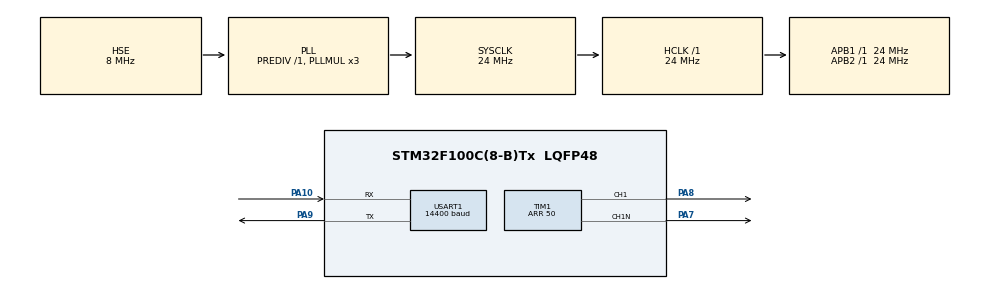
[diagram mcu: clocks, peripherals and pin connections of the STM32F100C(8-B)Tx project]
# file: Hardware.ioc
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Dma.Request0=USART1_TX
Dma.USART1_TX.0.Direction=DMA_MEMORY_TO_PERIPH
Dma.USART1_TX.0.Instance=DMA1_Channel4
Dma.USART1_TX.0.MemDataAlignment=DMA_MDATAALIGN_BYTE
Dma.USART1_TX.0.MemInc=DMA_MINC_ENABLE
Dma.USART1_TX.0.Mode=DMA_NORMAL
Dma.USART1_TX.0.PeriphDataAlignment=DMA_PDATAALIGN_BYTE
Dma.USART1_TX.0.PeriphInc=DMA_PINC_DISABLE
Dma.USART1_TX.0.Priority=DMA_PRIORITY_LOW
Mcu.Family=STM32F1
Mcu.Name=STM32F100C(8-B)Tx
Mcu.Package=LQFP48
NVIC.DMA1_Channel4_IRQn=true\:5\:0\:false\:false\:true\:true\:false
NVIC.PriorityGroup=NVIC_PRIORITYGROUP_4
NVIC.TIM3_IRQn=true\:5\:0\:false\:false\:true\:true\:true
NVIC.TIM7_IRQn=true\:0\:0\:false\:false\:true\:false\:false
NVIC.TimeBase=TIM7_IRQn
NVIC.TimeBaseIP=TIM7
NVIC.USART1_IRQn=true\:5\:0\:false\:false\:true\:true\:true
PA10.Mode=Asynchronous
PA10.Signal=USART1_RX
PA13.Mode=Serial_Wire
PA13.Signal=SYS_JTMS-SWDIO
PA14.Mode=Serial_Wire
PA14.Signal=SYS_JTCK-SWCLK
PA7.GPIO_Speed=GPIO_SPEED_FREQ_HIGH
PA7.Mode=PWM Generation1 CH1 CH1N
PA7.Signal=TIM1_CH1N
PA8.GPIO_Speed=GPIO_SPEED_FREQ_HIGH
PA8.Signal=S_TIM1_CH1
PA9.Mode=Asynchronous
PA9.Signal=USART1_TX
PD0-OSC_IN.Mode=HSE-External-Oscillator
PD0-OSC_IN.Signal=RCC_OSC_IN
PD1-OSC_OUT.Mode=HSE-External-Oscillator
PD1-OSC_OUT.Signal=RCC_OSC_OUT
ProjectManager.HeapSize=0x200
ProjectManager.StackSize=0x400
ProjectManager.TargetToolchain=SW4STM32
RCC.AHBFreq_Value=24000000
RCC.APB1Freq_Value=24000000
RCC.APB1TimFreq_Value=24000000
RCC.APB2Freq_Value=24000000
RCC.APB2TimFreq_Value=24000000
RCC.HCLKFreq_Value=24000000
RCC.PLLMUL=RCC_PLL_MUL3
RCC.PLLSource=RCC_PLLSOURCE_HSE
RCC.SYSCLKFreq_VALUE=24000000
RCC.SYSCLKSource=RCC_SYSCLKSOURCE_PLLCLK
SH.S_TIM1_CH1.0=TIM1_CH1,PWM Generation1 CH1 CH1N
TIM1.AutoReloadPreload=TIM_AUTORELOAD_PRELOAD_ENABLE
TIM1.Channel-PWM\ Generation1\ CH1\ CH1N=TIM_CHANNEL_1
TIM1.DeadTime=1
TIM1.Period=50
TIM1.Pulse-PWM\ Generation1\ CH1\ CH1N=25
TIM3.AutoReloadPreload=TIM_AUTORELOAD_PRELOAD_ENABLE
TIM3.Period=200
USART1.BaudRate=14400
USART1.VirtualMode=VM_ASYNC
VP_SYS_VS_tim7.Mode=TIM7
VP_TIM1_VS_ClockSourceINT.Mode=Internal
VP_TIM3_VS_ClockSourceINT.Mode=Internal
board=custom

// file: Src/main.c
/* USER CODE BEGIN Header */
/**
  ******************************************************************************
  * @file           : main.c
  * @brief          : Main program body
  ******************************************************************************
  * This notice applies to any and all portions of this file
  * that are not between comment pairs USER CODE BEGIN and
  * USER CODE END. Other portions of this file, whether
  * inserted by the user or by software development tools
  * are owned by their respective copyright owners.
  *
  * Copyright (c) 2019 STMicroelectronics International N.V.
  * All rights reserved.
  *
  * Redistribution and use in source and binary forms, with or without
  * modification, are permitted, provided that the following conditions are met:
  *
  * 1. Redistribution of source code must retain the above copyright notice,
  *    this list of conditions and the following disclaimer.
  * 2. Redistributions in binary form must reproduce the above copyright notice,
  *    this list of conditions and the following disclaimer in the documentation
  *    and/or other materials provided with the distribution.
  * 3. Neither the name of STMicroelectronics nor the names of other
  *    contributors to this software may be used to endorse or promote products
  *    derived from this software without specific written permission.
  * 4. This software, including modifications and/or derivative works of this
  *    software, must execute solely and exclusively on microcontroller or
  *    microprocessor devices manufactured by or for STMicroelectronics.
  * 5. Redistribution and use of this software other than as permitted under
  *    this license is void and will automatically terminate your rights under
  *    this license.
  *
  * THIS SOFTWARE IS PROVIDED BY STMICROELECTRONICS AND CONTRIBUTORS "AS IS"
  * AND ANY EXPRESS, IMPLIED OR STATUTORY WARRANTIES, INCLUDING, BUT NOT
  * LIMITED TO, THE IMPLIED WARRANTIES OF MERCHANTABILITY, FITNESS FOR A
  * PARTICULAR PURPOSE AND NON-INFRINGEMENT OF THIRD PARTY INTELLECTUAL PROPERTY
  * RIGHTS ARE DISCLAIMED TO THE FULLEST EXTENT PERMITTED BY LAW. IN NO EVENT
  * SHALL STMICROELECTRONICS OR CONTRIBUTORS BE LIABLE FOR ANY DIRECT, INDIRECT,
  * INCIDENTAL, SPECIAL, EXEMPLARY, OR CONSEQUENTIAL DAMAGES (INCLUDING, BUT NOT
  * LIMITED TO, PROCUREMENT OF SUBSTITUTE GOODS OR SERVICES; LOSS OF USE, DATA,
  * OR PROFITS; OR BUSINESS INTERRUPTION) HOWEVER CAUSED AND ON ANY THEORY OF
  * LIABILITY, WHETHER IN CONTRACT, STRICT LIABILITY, OR TORT (INCLUDING
  * NEGLIGENCE OR OTHERWISE) ARISING IN ANY WAY OUT OF THE USE OF THIS SOFTWARE,
  * EVEN IF ADVISED OF THE POSSIBILITY OF SUCH DAMAGE.
  *
  ******************************************************************************
  */
/* USER CODE END Header */

#include "main.h"
#include "cmsis_os.h"

/* USER CODE BEGIN Includes */
#include "common.h"
#include "packet_manager.h"
#include "kernel.h"
/* USER CODE END Includes */

TIM_HandleTypeDef htim1;
TIM_HandleTypeDef htim3;

UART_HandleTypeDef huart1;
DMA_HandleTypeDef hdma_usart1_tx;

osThreadId defaultTaskHandle;

void SystemClock_Config(void);
static void MX_GPIO_Init(void);
static void MX_DMA_Init(void);
static void MX_TIM1_Init(void);
static void MX_USART1_UART_Init(void);
static void MX_TIM3_Init(void);
void StartDefaultTask(void const * argument);

int main(void)
{

  /* MCU Configuration--------------------------------------------------------*/

  /* Reset of all peripherals, Initializes the Flash interface and the Systick. */
  HAL_Init();

  /* Configure the system clock */
  SystemClock_Config();

  /* Initialize all configured peripherals */
  MX_GPIO_Init();
  MX_DMA_Init();
  MX_TIM1_Init();
  MX_USART1_UART_Init();
  MX_TIM3_Init();

  /* Create the thread(s) */
  /* definition and creation of defaultTask */
  osThreadDef(defaultTask, StartDefaultTask, osPriorityNormal, 0, 128);
  defaultTaskHandle = osThreadCreate(osThread(defaultTask), NULL);

  /* Start scheduler */
  osKernelStart();

  /* We should never get here as control is now taken by the scheduler */

  /* Infinite loop */
  while (1)
  {

  }
}

void SystemClock_Config(void)
{
  RCC_OscInitTypeDef RCC_OscInitStruct = {0};
  RCC_ClkInitTypeDef RCC_ClkInitStruct = {0};

  /**Initializes the CPU, AHB and APB busses clocks
  */
  RCC_OscInitStruct.OscillatorType = RCC_OSCILLATORTYPE_HSE;
  RCC_OscInitStruct.HSEState = RCC_HSE_ON;
  RCC_OscInitStruct.HSEPredivValue = RCC_HSE_PREDIV_DIV1;
  RCC_OscInitStruct.PLL.PLLState = RCC_PLL_ON;
  RCC_OscInitStruct.PLL.PLLSource = RCC_PLLSOURCE_HSE;
  RCC_OscInitStruct.PLL.PLLMUL = RCC_PLL_MUL3;
  if (HAL_RCC_OscConfig(&RCC_OscInitStruct) != HAL_OK)
  {
    Error_Handler();
  }
  /**Initializes the CPU, AHB and APB busses clocks
  */
  RCC_ClkInitStruct.ClockType = RCC_CLOCKTYPE_HCLK|RCC_CLOCKTYPE_SYSCLK
                              |RCC_CLOCKTYPE_PCLK1|RCC_CLOCKTYPE_PCLK2;
  RCC_ClkInitStruct.SYSCLKSource = RCC_SYSCLKSOURCE_PLLCLK;
  RCC_ClkInitStruct.AHBCLKDivider = RCC_SYSCLK_DIV1;
  RCC_ClkInitStruct.APB1CLKDivider = RCC_HCLK_DIV1;
  RCC_ClkInitStruct.APB2CLKDivider = RCC_HCLK_DIV1;

  if (HAL_RCC_ClockConfig(&RCC_ClkInitStruct, FLASH_LATENCY_0) != HAL_OK)
  {
    Error_Handler();
  }
}

static void MX_TIM1_Init(void)
{

  TIM_ClockConfigTypeDef sClockSourceConfig = {0};
  TIM_MasterConfigTypeDef sMasterConfig = {0};
  TIM_OC_InitTypeDef sConfigOC = {0};
  TIM_BreakDeadTimeConfigTypeDef sBreakDeadTimeConfig = {0};

  htim1.Instance = TIM1;
  htim1.Init.Prescaler = 0;
  htim1.Init.CounterMode = TIM_COUNTERMODE_UP;
  htim1.Init.Period = 50;
  htim1.Init.ClockDivision = TIM_CLOCKDIVISION_DIV1;
  htim1.Init.RepetitionCounter = 0;
  htim1.Init.AutoReloadPreload = TIM_AUTORELOAD_PRELOAD_ENABLE;
  if (HAL_TIM_Base_Init(&htim1) != HAL_OK)
  {
    Error_Handler();
  }
  sClockSourceConfig.ClockSource = TIM_CLOCKSOURCE_INTERNAL;
  if (HAL_TIM_ConfigClockSource(&htim1, &sClockSourceConfig) != HAL_OK)
  {
    Error_Handler();
  }
  if (HAL_TIM_PWM_Init(&htim1) != HAL_OK)
  {
    Error_Handler();
  }
  sMasterConfig.MasterOutputTrigger = TIM_TRGO_RESET;
  sMasterConfig.MasterSlaveMode = TIM_MASTERSLAVEMODE_DISABLE;
  if (HAL_TIMEx_MasterConfigSynchronization(&htim1, &sMasterConfig) != HAL_OK)
  {
    Error_Handler();
  }
  sConfigOC.OCMode = TIM_OCMODE_PWM1;
  sConfigOC.Pulse = 25;
  sConfigOC.OCPolarity = TIM_OCPOLARITY_HIGH;
  sConfigOC.OCNPolarity = TIM_OCNPOLARITY_HIGH;
  sConfigOC.OCFastMode = TIM_OCFAST_DISABLE;
  sConfigOC.OCIdleState = TIM_OCIDLESTATE_RESET;
  sConfigOC.OCNIdleState = TIM_OCNIDLESTATE_RESET;
  if (HAL_TIM_PWM_ConfigChannel(&htim1, &sConfigOC, TIM_CHANNEL_1) != HAL_OK)
  {
    Error_Handler();
  }
  sBreakDeadTimeConfig.OffStateRunMode = TIM_OSSR_DISABLE;
  sBreakDeadTimeConfig.OffStateIDLEMode = TIM_OSSI_DISABLE;
  sBreakDeadTimeConfig.LockLevel = TIM_LOCKLEVEL_OFF;
  sBreakDeadTimeConfig.DeadTime = 1;
  sBreakDeadTimeConfig.BreakState = TIM_BREAK_DISABLE;
  sBreakDeadTimeConfig.BreakPolarity = TIM_BREAKPOLARITY_HIGH;
  sBreakDeadTimeConfig.AutomaticOutput = TIM_AUTOMATICOUTPUT_DISABLE;
  if (HAL_TIMEx_ConfigBreakDeadTime(&htim1, &sBreakDeadTimeConfig) != HAL_OK)
  {
    Error_Handler();
  }
  HAL_TIM_MspPostInit(&htim1);

}

static void MX_TIM3_Init(void)
{

  TIM_ClockConfigTypeDef sClockSourceConfig = {0};
  TIM_MasterConfigTypeDef sMasterConfig = {0};

  htim3.Instance = TIM3;
  htim3.Init.Prescaler = 0;
  htim3.Init.CounterMode = TIM_COUNTERMODE_UP;
  htim3.Init.Period = 200;
  htim3.Init.ClockDivision = TIM_CLOCKDIVISION_DIV1;
  htim3.Init.AutoReloadPreload = TIM_AUTORELOAD_PRELOAD_ENABLE;
  if (HAL_TIM_Base_Init(&htim3) != HAL_OK)
  {
    Error_Handler();
  }
  sClockSourceConfig.ClockSource = TIM_CLOCKSOURCE_INTERNAL;
  if (HAL_TIM_ConfigClockSource(&htim3, &sClockSourceConfig) != HAL_OK)
  {
    Error_Handler();
  }
  sMasterConfig.MasterOutputTrigger = TIM_TRGO_RESET;
  sMasterConfig.MasterSlaveMode = TIM_MASTERSLAVEMODE_DISABLE;
  if (HAL_TIMEx_MasterConfigSynchronization(&htim3, &sMasterConfig) != HAL_OK)
  {
    Error_Handler();
  }

}

static void MX_USART1_UART_Init(void)
{

  huart1.Instance = USART1;
  huart1.Init.BaudRate = 14400;
  huart1.Init.WordLength = UART_WORDLENGTH_8B;
  huart1.Init.StopBits = UART_STOPBITS_1;
  huart1.Init.Parity = UART_PARITY_NONE;
  huart1.Init.Mode = UART_MODE_TX_RX;
  huart1.Init.HwFlowCtl = UART_HWCONTROL_NONE;
  huart1.Init.OverSampling = UART_OVERSAMPLING_16;
  if (HAL_UART_Init(&huart1) != HAL_OK)
  {
    Error_Handler();
  }

}

static void MX_DMA_Init(void)
{
  /* DMA controller clock enable */
  __HAL_RCC_DMA1_CLK_ENABLE();

  /* DMA interrupt init */
  /* DMA1_Channel4_IRQn interrupt configuration */
  HAL_NVIC_SetPriority(DMA1_Channel4_IRQn, 5, 0);
  HAL_NVIC_EnableIRQ(DMA1_Channel4_IRQn);

}

static void MX_GPIO_Init(void)
{

  /* GPIO Ports Clock Enable */
  __HAL_RCC_GPIOD_CLK_ENABLE();
  __HAL_RCC_GPIOA_CLK_ENABLE();

}

void StartDefaultTask(void const * argument)
{

  /* USER CODE BEGIN 5 */
  /* Infinite loop */
  	PM_Init();
  	KERNEL_Init();
	PM_Task();

  for(;;)
  {
    osDelay(100);
  }
  /* USER CODE END 5 */
}

void HAL_TIM_PeriodElapsedCallback(TIM_HandleTypeDef *htim)
{
  if (htim->Instance == TIM7) {
    HAL_IncTick();
  }
  /* USER CODE BEGIN Callback 1 */
  else{
	  KERNEL_PeriodElapsedCallback(htim);
  }
  /* USER CODE END Callback 1 */
}

void Error_Handler(void)
{
}

/************************ (C) COPYRIGHT STMicroelectronics *****END OF FILE****/
